VERSION ""

NS_ :

BS_:

BU_: XXX

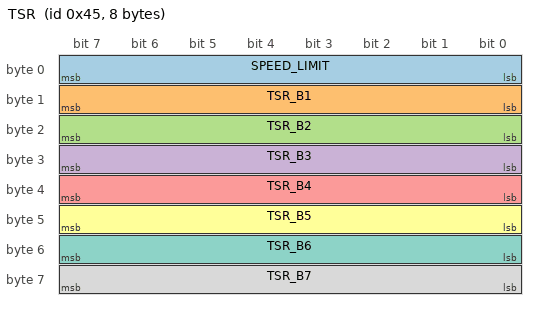
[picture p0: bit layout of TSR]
BO_ 69 TSR: 8 XXX
 SG_ SPEED_LIMIT : 0|8@1+ (1,0) [0|255] "kph" XXX
 SG_ TSR_B1 : 8|8@1+ (1,0) [0|255] "" XXX
 SG_ TSR_B2 : 16|8@1+ (1,0) [0|255] "" XXX
 SG_ TSR_B3 : 24|8@1+ (1,0) [0|255] "" XXX
 SG_ TSR_B4 : 32|8@1+ (1,0) [0|255] "" XXX
 SG_ TSR_B5 : 40|8@1+ (1,0) [0|255] "" XXX
 SG_ TSR_B6 : 48|8@1+ (1,0) [0|255] "" XXX
 SG_ TSR_B7 : 56|8@1+ (1,0) [0|255] "" XXX
